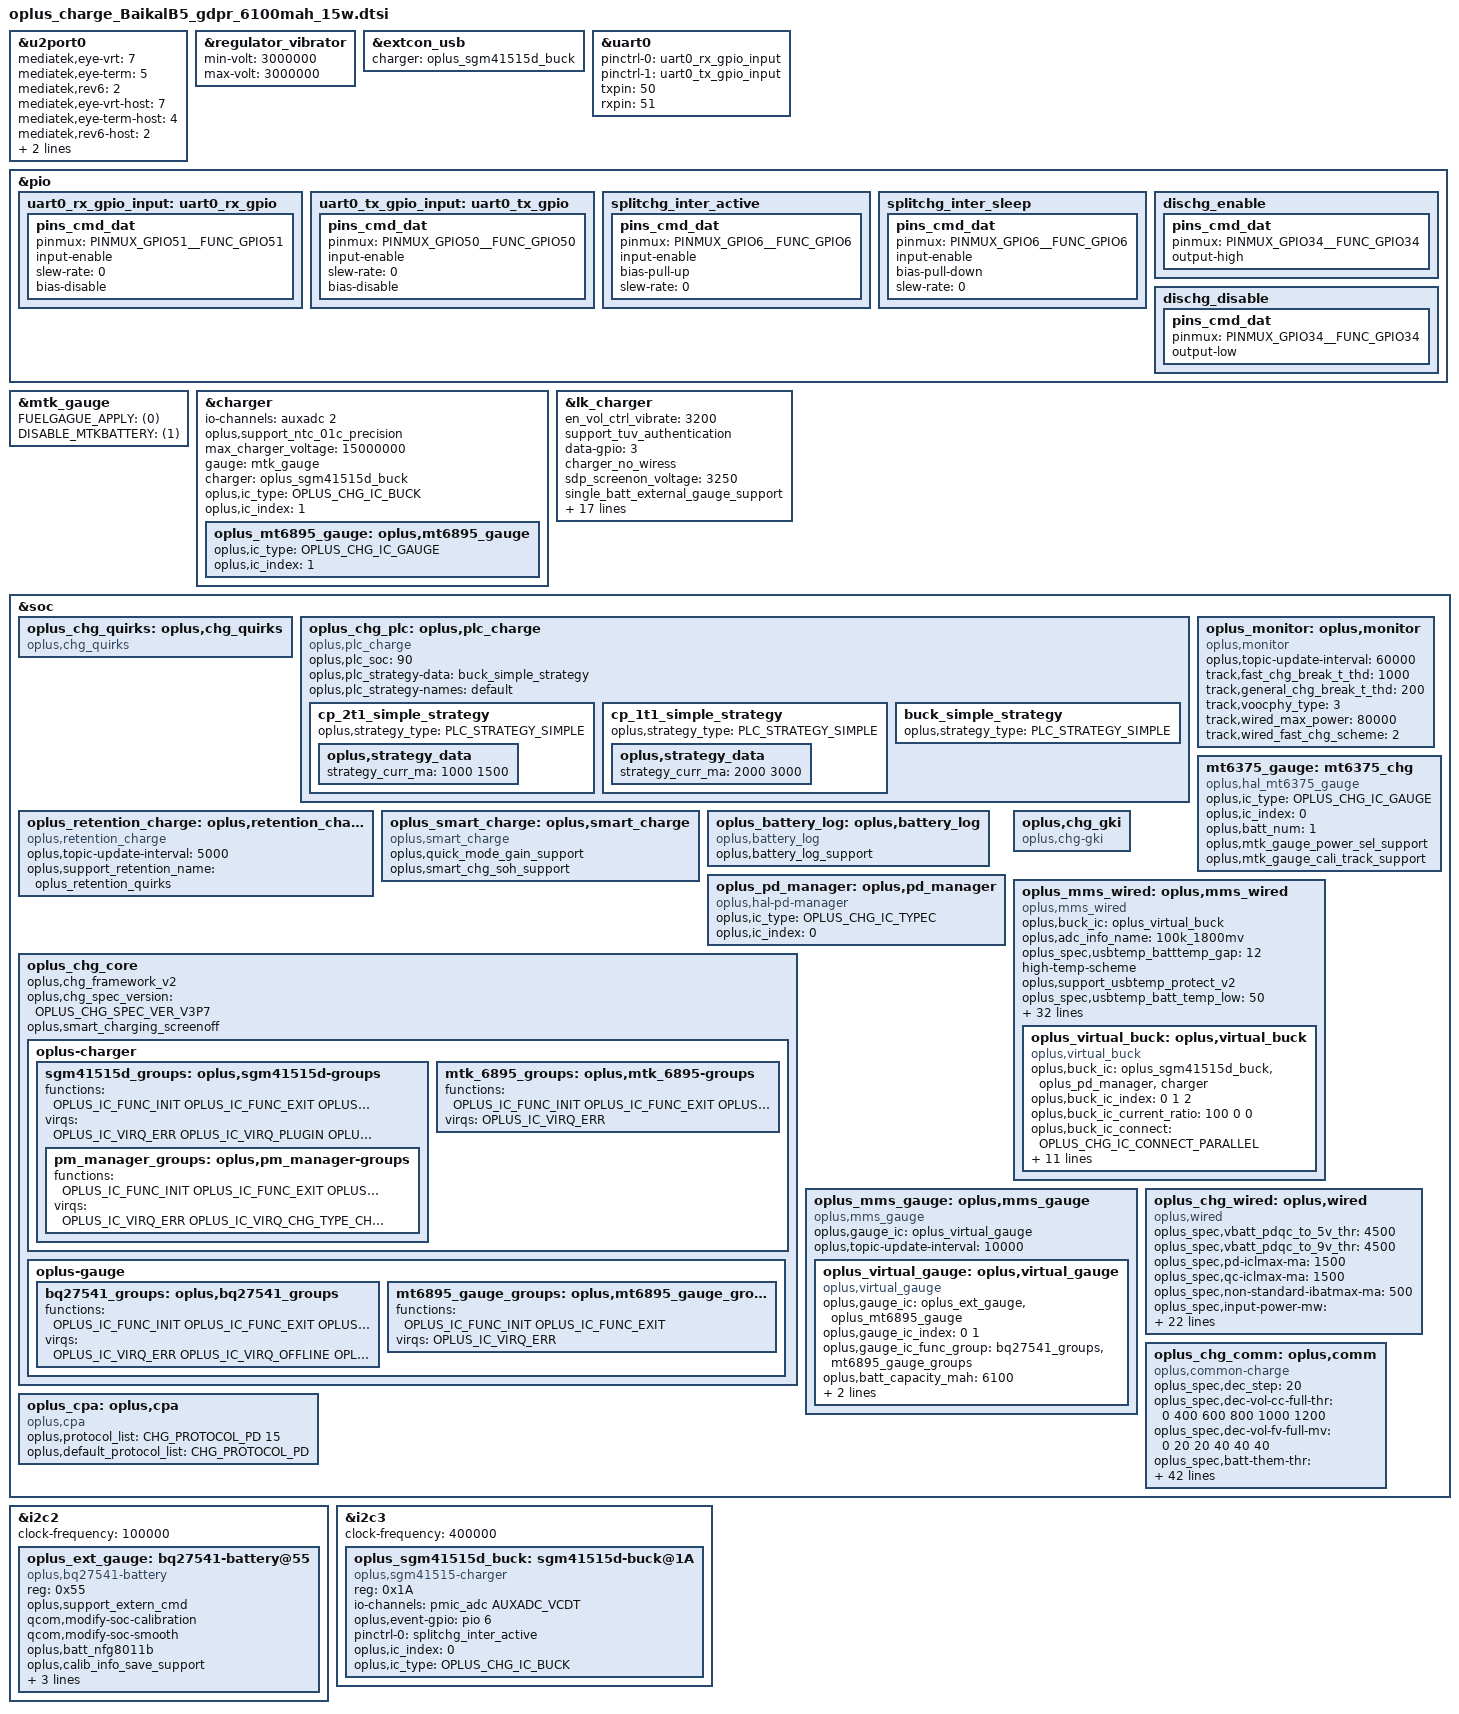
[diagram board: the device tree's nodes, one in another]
// SPDX-License-Identifier: GPL-2.0-only
/*
* Copyright (C) 2021-2020 Oplus. All rights reserved.
*/

/*
 * CPU:MT6835
 * Project:Baikal-B5
 * Module:CHG dtsi 15W support PD
 *
 * UART
 * UTXD0 -->GPIO50
 * URXD0 -->GPIO51
 *
 * I2C
 * MASTER_CHG(SGM41515D)        --> I2C3
 * CCLOGIC(AW35615)             --> I2C3
 * GAUGE                        --> I2C2
 *
 * IRQ
 * EINT5(PD IRQ)                -->GPIO5
 * EINT6(CHG IRQ)               -->GPIO6
 *
 * GPIO
 * MAIN/CCLOGIN_SCL             --> GPIO133(SCL3)
 * MAIN/CCLOGIN_SDA             --> GPIO134(SDA3)
 * GAUGE_SCL                    --> GPIO131(SCL2)
 * GAUGE_SDA                    --> GPIO132(SDA2)
 * VBUS_SHORT(防烧口)            --> GPIO34
 *
 * AP_AUXADC:
 * 0				--> FLASH_LED_NTC (flash light temperature)
 * 1				--> NA
 * 2				--> CHG_NTC(SGM41515D charger temperature)
 * 3				--> USB_TEM_ADC_PMU1(usb btb temperature)
 * 4				--> USB_TEM_ADC_PMU2(usb btb temperature)
 * 5				--> BAT_ID(battery id detect)
 * 6				-->
 * 7				-->
 * 8				-->
 */

#include <dt-bindings/iio/mt635x-auxadc.h>
#include <dt-bindings/pinctrl/mt6373-pinfunc.h>
#include <dt-bindings/pinctrl/mt65xx.h>
#include "oplus_chg.h"

&u2port0 {
	mediatek,eye-vrt = <7>;
	mediatek,eye-term= <5>;
	mediatek,rev6 = <2>;
	mediatek,eye-vrt-host = <7>;
	mediatek,eye-term-host = <4>;
	mediatek,rev6-host = <2>;
	mediatek,discth = <0xc>;
	mediatek,rx-sqth = <3>;
};

&regulator_vibrator{
	min-volt = <3000000>;
	max-volt = <3000000>;
};

&extcon_usb {
	charger = <&oplus_sgm41515d_buck>;
	status = "okay";
};

&uart0 {
	pinctrl-names = "uart0_rx_gpio", "uart0_tx_gpio";
	pinctrl-0 = <&uart0_rx_gpio_input>;
	pinctrl-1 = <&uart0_tx_gpio_input>;
	status = "okay";

	txpin = <50>;
	rxpin = <51>;
};

&pio {
	uart0_rx_gpio_input: uart0_rx_gpio {
		pins_cmd_dat {
			pinmux = <PINMUX_GPIO51__FUNC_GPIO51>;
			input-enable;
			slew-rate = <0>;
			bias-disable;
		};
	};

	uart0_tx_gpio_input: uart0_tx_gpio {
		pins_cmd_dat {
			pinmux = <PINMUX_GPIO50__FUNC_GPIO50>;
			input-enable;
			slew-rate = <0>;
			bias-disable;
		};
	};
	/*split_chg*/
	splitchg_inter_active: splitchg_inter_active {
		pins_cmd_dat {
			pinmux = <PINMUX_GPIO6__FUNC_GPIO6>;
			input-enable;
			bias-pull-up;
			slew-rate = <0>;
		};
	};
	splitchg_inter_sleep: splitchg_inter_sleep {
		pins_cmd_dat {
			pinmux = <PINMUX_GPIO6__FUNC_GPIO6>;
			input-enable;
			bias-pull-down;
			slew-rate = <0>;
		};
	};
	/*VBUS_SHORT*/
	dischg_enable: dischg_enable {
		pins_cmd_dat {
			pinmux = <PINMUX_GPIO34__FUNC_GPIO34>;
			output-high;
		};
	};
	dischg_disable: dischg_disable {
		pins_cmd_dat {
			pinmux = <PINMUX_GPIO34__FUNC_GPIO34>;
			output-low;
		};
	};
};


&mtk_gauge {
	FUELGAGUE_APPLY = <(0)>;
	DISABLE_MTKBATTERY = <(1)>;
};

&charger {
	io-channels = <&auxadc 2>;
	io-channel-names = "auxadc5-chargeric_temp";
	oplus,support_ntc_01c_precision;
	max_charger_voltage = <15000000>;
	gauge = <&mtk_gauge>;
	charger = <&oplus_sgm41515d_buck>;

	oplus,ic_type = <OPLUS_CHG_IC_BUCK>;
	oplus,ic_index = <1>;

	oplus_mt6895_gauge: oplus,mt6895_gauge {
		oplus,ic_type = <OPLUS_CHG_IC_GAUGE>;
		oplus,ic_index = <1>;
	};
};

&lk_charger {
	en_vol_ctrl_vibrate = <3200>;
	support_tuv_authentication;
	data-gpio = <3>;
	charger_no_wiress;
	sdp_screenon_voltage = <3250>;
	single_batt_external_gauge_support;
	support_sdp_screenoff;
	support_sdp_backlight;
	led_brightness = <102>;
	high-temp-scheme;
	over_high_temp_thr = <60>;
	charger_i2c_bus_id = <0x03>;
	support_quickboot_charge;
	support_4p48_single_battery;//待确定
	max_charger_voltage = <15000000>;
	boot_battery_voltage = <3400000>;
	usb_charger_current = <500000>;
	ac_charger_current = <2050000>;
	ac_charger_input_current = <1500000>;
	non_std_ac_charger_current = <750000>;
	charging_host_charger_current = <1500000>;
	ta_ac_charger_current = <1500000>;
	pd_charger_current = <500000>;
};

&soc {
	oplus_chg_quirks: oplus,chg_quirks {
		compatible = "oplus,chg_quirks";
	};

	oplus_chg_plc: oplus,plc_charge {
		compatible = "oplus,plc_charge";
		oplus,plc_soc = <90>;
		oplus,plc_strategy-data = <&buck_simple_strategy>;
		oplus,plc_strategy-names = "default";

		cp_2t1_simple_strategy: cp_2t1_simple_strategy {
			oplus,strategy_type = <PLC_STRATEGY_SIMPLE>;
			oplus,strategy_data {
				strategy_curr_ma = <1000 1500>;
			};
		};

		cp_1t1_simple_strategy: cp_1t1_simple_strategy {
			oplus,strategy_type = <PLC_STRATEGY_SIMPLE>;
			oplus,strategy_data {
				strategy_curr_ma = <2000 3000>;
			};
		};

		buck_simple_strategy: buck_simple_strategy {
			oplus,strategy_type = <PLC_STRATEGY_SIMPLE>;
		};
	};

	oplus_retention_charge: oplus,retention_charge {
		compatible = "oplus,retention_charge";
		oplus,topic-update-interval = <5000>;
		oplus,support_retention_name = "oplus_retention_quirks";
	};

	oplus_smart_charge: oplus,smart_charge {
		compatible = "oplus,smart_charge";
		oplus,quick_mode_gain_support;
		oplus,smart_chg_soh_support;
	};

	oplus_battery_log: oplus,battery_log {
		compatible = "oplus,battery_log";
		oplus,battery_log_support;
	};

	oplus_monitor: oplus,monitor {
		compatible = "oplus,monitor";
		oplus,topic-update-interval = <60000>;

		track,fast_chg_break_t_thd = <1000>;
		track,general_chg_break_t_thd = <200>;
		track,voocphy_type = <3>;
		track,wired_max_power = <80000>;
		track,wired_fast_chg_scheme = <2>;
	};

	mt6375_gauge: mt6375_chg {
		status = "okay";
		compatible = "oplus,hal_mt6375_gauge";

		oplus,ic_type = <OPLUS_CHG_IC_GAUGE>;
		oplus,ic_index = <0>;
		oplus,batt_num = <1>;
		oplus,mtk_gauge_power_sel_support;
		oplus,mtk_gauge_cali_track_support;
	};

	oplus_pd_manager: oplus,pd_manager{
		compatible = "oplus,hal-pd-manager";
		oplus,ic_type = <OPLUS_CHG_IC_TYPEC>;
		oplus,ic_index = <0>;
	};

	oplus,chg_gki {
		compatible = "oplus,chg-gki";
	};

	oplus_chg_core {
		oplus,chg_framework_v2;
		oplus,chg_spec_version = <OPLUS_CHG_SPEC_VER_V3P7>;
		oplus,smart_charging_screenoff;

		oplus-charger {
			sgm41515d_groups: oplus,sgm41515d-groups {
				functions = <
					OPLUS_IC_FUNC_INIT
					OPLUS_IC_FUNC_EXIT
					OPLUS_IC_FUNC_REG_DUMP
					OPLUS_IC_FUNC_SMT_TEST
					OPLUS_IC_FUNC_BUCK_INPUT_PRESENT
					OPLUS_IC_FUNC_BUCK_INPUT_SUSPEND
					OPLUS_IC_FUNC_BUCK_INPUT_IS_SUSPEND
					OPLUS_IC_FUNC_BUCK_OUTPUT_SUSPEND
					OPLUS_IC_FUNC_BUCK_OUTPUT_IS_SUSPEND
					OPLUS_IC_FUNC_BUCK_SET_ICL
					OPLUS_IC_FUNC_BUCK_GET_ICL
					OPLUS_IC_FUNC_BUCK_SET_FCC
					OPLUS_IC_FUNC_BUCK_SET_FV
					OPLUS_IC_FUNC_BUCK_SET_ITERM
					OPLUS_IC_FUNC_BUCK_SET_RECHG_VOL
					OPLUS_IC_FUNC_BUCK_GET_INPUT_CURR
					OPLUS_IC_FUNC_BUCK_GET_INPUT_VOL
					OPLUS_IC_FUNC_OTG_BOOST_ENABLE
					OPLUS_IC_FUNC_SET_OTG_BOOST_VOL
					OPLUS_IC_FUNC_SET_OTG_BOOST_CURR_LIMIT
					OPLUS_IC_FUNC_BUCK_AICL_ENABLE
					OPLUS_IC_FUNC_BUCK_AICL_RERUN
					OPLUS_IC_FUNC_BUCK_AICL_RESET
					OPLUS_IC_FUNC_BUCK_GET_CHARGER_TYPE
					OPLUS_IC_FUNC_BUCK_RERUN_BC12
					OPLUS_IC_FUNC_BUCK_QC_DETECT_ENABLE
					OPLUS_IC_FUNC_BUCK_SET_QC_CONFIG
					OPLUS_IC_FUNC_BUCK_SHIPMODE_ENABLE
					//OPLUS_IC_FUNC_BUCK_GET_USB_BTB_TEMP
					//OPLUS_IC_FUNC_BUCK_GET_BATT_BTB_TEMP
					OPLUS_IC_FUNC_BUCK_SET_AICL_POINT
					OPLUS_IC_FUNC_BUCK_HARDWARE_INIT
					OPLUS_IC_FUNC_BUCK_KICK_WDT
				>;
				virqs = <
					OPLUS_IC_VIRQ_ERR
					OPLUS_IC_VIRQ_PLUGIN
					OPLUS_IC_VIRQ_CHG_TYPE_CHANGE
					OPLUS_IC_VIRQ_BC12_COMPLETED
				>;
				pm_manager_groups: oplus,pm_manager-groups {
					functions = <
						OPLUS_IC_FUNC_INIT
						OPLUS_IC_FUNC_EXIT
						OPLUS_IC_FUNC_REG_DUMP
						OPLUS_IC_FUNC_SMT_TEST
						OPLUS_IC_FUNC_BUCK_GET_CHARGER_TYPE
						OPLUS_IC_FUNC_BUCK_GET_CC_ORIENTATION
						OPLUS_IC_FUNC_BUCK_SET_PD_CONFIG
						OPLUS_IC_FUNC_GET_TYPEC_MODE
						OPLUS_IC_FUNC_SET_TYPEC_MODE
						OPLUS_IC_FUNC_GET_TYPEC_ROLE
						OPLUS_IC_FUNC_GET_CHARGER_VOL_MAX
						OPLUS_IC_FUNC_GET_CHARGER_VOL_MIN
						OPLUS_IC_FUNC_GET_CHARGER_CURR_MAX
						OPLUS_IC_FUNC_BUCK_BC12_COMPLETED
						OPLUS_IC_FUNC_GET_OTG_ENABLE
						OPLUS_IC_FUNC_IS_OPLUS_SVID
						OPLUS_IC_FUNC_GET_DATA_ROLE
						OPLUS_IC_FUNC_FIXED_PDO_SET
						OPLUS_IC_FUNC_PPS_PDO_SET
						OPLUS_IC_FUNC_PPS_GET_PDO_INFO
					>;
					virqs = <
						OPLUS_IC_VIRQ_ERR
						OPLUS_IC_VIRQ_CHG_TYPE_CHANGE
						OPLUS_IC_VIRQ_SVID
						OPLUS_IC_VIRQ_VOLTAGE_CHANGED
						OPLUS_IC_VIRQ_CURRENT_CHANGED
						OPLUS_IC_VIRQ_OTG_ENABLE
						OPLUS_IC_VIRQ_DATA_ROLE_CHANGED
					>;
				};
			};
			mtk_6895_groups: oplus,mtk_6895-groups {
				functions = <
					OPLUS_IC_FUNC_INIT
					OPLUS_IC_FUNC_EXIT
					OPLUS_IC_FUNC_REG_DUMP
					OPLUS_IC_FUNC_SMT_TEST
				>;
				virqs = <
					OPLUS_IC_VIRQ_ERR
				>;
			};

		};

		oplus-gauge {
			bq27541_groups: oplus,bq27541_groups {
				functions = <
					OPLUS_IC_FUNC_INIT
					OPLUS_IC_FUNC_EXIT
					OPLUS_IC_FUNC_REG_DUMP
					OPLUS_IC_FUNC_SMT_TEST
					OPLUS_IC_FUNC_GAUGE_GET_BATT_VOL
					OPLUS_IC_FUNC_GAUGE_GET_BATT_MAX
					OPLUS_IC_FUNC_GAUGE_GET_BATT_MIN
					OPLUS_IC_FUNC_GAUGE_GET_BATT_CURR
					OPLUS_IC_FUNC_GAUGE_GET_BATT_TEMP
					OPLUS_IC_FUNC_GAUGE_GET_BATT_SOC
					OPLUS_IC_FUNC_GAUGE_GET_BATT_FCC
					OPLUS_IC_FUNC_GAUGE_GET_BATT_CC
					OPLUS_IC_FUNC_GAUGE_GET_BATT_RM
					OPLUS_IC_FUNC_GAUGE_GET_BATT_SOH
					OPLUS_IC_FUNC_GAUGE_GET_BATT_AUTH
					OPLUS_IC_FUNC_GAUGE_GET_BATT_HMAC
					OPLUS_IC_FUNC_GAUGE_SET_BATT_FULL
					OPLUS_IC_FUNC_GAUGE_UPDATE_DOD0
					OPLUS_IC_FUNC_GAUGE_UPDATE_SOC_SMOOTH
					OPLUS_IC_FUNC_GAUGE_GET_CB_STATUS
					OPLUS_IC_FUNC_GAUGE_GET_BATT_NUM
					OPLUS_IC_FUNC_GAUGE_GET_DEVICE_TYPE
					OPLUS_IC_FUNC_GAUGE_GET_DEVICE_TYPE_FOR_VOOC
					OPLUS_IC_FUNC_GAUGE_GET_BATT_FCC
					OPLUS_IC_FUNC_GAUGE_GET_BATT_FC
					OPLUS_IC_FUNC_GAUGE_GET_BATT_QM
					OPLUS_IC_FUNC_GAUGE_GET_BATT_PD
					OPLUS_IC_FUNC_GAUGE_GET_BATT_RCU
					OPLUS_IC_FUNC_GAUGE_GET_BATT_RCF
					OPLUS_IC_FUNC_GAUGE_GET_BATT_FCU
					OPLUS_IC_FUNC_GAUGE_GET_BATT_FCF
					OPLUS_IC_FUNC_GAUGE_GET_BATT_SOU
					OPLUS_IC_FUNC_GAUGE_GET_BATT_DO0
					OPLUS_IC_FUNC_GAUGE_GET_BATT_DOE
					OPLUS_IC_FUNC_GAUGE_GET_BATT_TRM
					OPLUS_IC_FUNC_GAUGE_GET_BATT_PC
					OPLUS_IC_FUNC_GAUGE_GET_BATT_QS
					OPLUS_IC_FUNC_GAUGE_IS_SUSPEND
					OPLUS_IC_FUNC_GAUGE_GET_BCC_PARMS
					OPLUS_IC_FUNC_GAUGE_FASTCHG_UPDATE_BCC_PARMS
					OPLUS_IC_FUNC_GAUGE_GET_PREV_BCC_PARMS
					OPLUS_IC_FUNC_GAUGE_SET_BCC_PARMS
					OPLUS_IC_FUNC_GAUGE_SET_PROTECT_CHECK
					OPLUS_IC_FUNC_GAUGE_GET_AFI_UPDATE_DONE
					OPLUS_IC_FUNC_GAUGE_CHECK_RESET
					OPLUS_IC_FUNC_GAUGE_SET_RESET
					OPLUS_IC_FUNC_GAUGE_GET_DEVICE_TYPE_FOR_BCC
					OPLUS_IC_FUNC_GAUGE_GET_DOD0
					OPLUS_IC_FUNC_GAUGE_GET_DOD0_PASSED_Q
					OPLUS_IC_FUNC_GAUGE_GET_QMAX
					OPLUS_IC_FUNC_GAUGE_GET_QMAX_PASSED_Q
					OPLUS_IC_FUNC_GAUGE_GET_REG_INFO
					OPLUS_IC_FUNC_GAUGE_GET_CALIB_TIME
					OPLUS_IC_FUNC_GAUGE_GET_GAUGE_TYPE
					OPLUS_IC_FUNC_GAUGE_GET_BATT_SN
					OPLUS_IC_FUNC_GAUGE_GET_MANU_DATE
					OPLUS_IC_FUNC_GAUGE_GET_FIRST_USAGE_DATE
					OPLUS_IC_FUNC_GAUGE_SET_FIRST_USAGE_DATE
					OPLUS_IC_FUNC_GAUGE_GET_UI_CC
					OPLUS_IC_FUNC_GAUGE_SET_UI_CC
					OPLUS_IC_FUNC_GAUGE_GET_UI_SOH
					OPLUS_IC_FUNC_GAUGE_SET_UI_SOH
					OPLUS_IC_FUNC_GAUGE_GET_USED_FLAG
					OPLUS_IC_FUNC_GAUGE_SET_USED_FLAG
					OPLUS_IC_FUNC_GAUGE_SET_SEAL_FLAG
				>;
				virqs = <
					OPLUS_IC_VIRQ_ERR
					OPLUS_IC_VIRQ_OFFLINE
					OPLUS_IC_VIRQ_RESUME
				>;
			};

			mt6895_gauge_groups: oplus,mt6895_gauge_groups {
				functions = <
					OPLUS_IC_FUNC_INIT
					OPLUS_IC_FUNC_EXIT
				>;
				virqs = <
					OPLUS_IC_VIRQ_ERR
				>;
			};
		};
	};
};

&soc {
	oplus_mms_wired: oplus,mms_wired {
		compatible = "oplus,mms_wired";
		oplus,buck_ic = <&oplus_virtual_buck>;
		oplus,adc_info_name = "100k_1800mv";
		oplus_spec,usbtemp_batttemp_gap = <12>;
		high-temp-scheme;

		oplus,support_usbtemp_protect_v2;
		oplus_spec,usbtemp_batt_temp_low = <50>;
		oplus_spec,usbtemp_batt_temp_high = <50>;
		oplus_spec,usbtemp_batt_temp_over_hot = <60>;
		oplus_spec,usbtemp_ntc_temp_low = <57>;
		oplus_spec,usbtemp_ntc_temp_high = <69>;
		oplus_spec,usbtemp_temp_gap_low_with_batt_temp = <7>;
		oplus_spec,usbtemp_temp_gap_with_batt_temp_in_over_hot = <15>;
		oplus_spec,usbtemp_temp_gap_high_with_batt_temp = <12>;
		oplus_spec,usbtemp_temp_gap_low_without_batt_temp = <12>;
		oplus_spec,usbtemp_temp_gap_high_without_batt_temp = <24>;
		oplus_spec,usbtemp_rise_fast_temp_low = <3>;
		oplus_spec,usbtemp_rise_fast_temp_high = <3>;
		oplus_spec,usbtemp_rise_fast_temp_count_low = <30>;
		oplus_spec,usbtemp_rise_fast_temp_count_high = <20>;
		oplus_spec,usbtemp_cool_down_ntc_low = <54>;
		oplus_spec,usbtemp_cool_down_ntc_high = <65>;
		oplus_spec,usbtemp_cool_down_gap_low = <12>;
		oplus_spec,usbtemp_cool_down_gap_high = <20>;
		oplus_spec,usbtemp_cool_down_recover_ntc_low = <48>;
		oplus_spec,usbtemp_cool_down_recover_ntc_high = <60>;
		oplus_spec,usbtemp_cool_down_recover_gap_low = <6>;
		oplus_spec,usbtemp_cool_down_recover_gap_high = <15>;
		oplus_virtual_buck: oplus,virtual_buck {
			compatible = "oplus,virtual_buck";
			oplus,buck_ic = <&oplus_sgm41515d_buck &oplus_pd_manager &charger>;
			oplus,buck_ic_index = <0 1 2>;
			oplus,buck_ic_current_ratio = <100 0 0>;
			oplus,buck_ic_connect = <OPLUS_CHG_IC_CONNECT_PARALLEL>;
			oplus,main_charger = <0>;
			oplus,buck_ic_func_group = <&sgm41515d_groups &pm_manager_groups &mtk_6895_groups>;
			oplus,ic_type = <OPLUS_CHG_IC_VIRTUAL_BUCK>;
			oplus,ic_index = <0>;
			oplus,dischg-gpio = <&pio 34 0x00>;/*VBUS_SHORT*/
			oplus,uart_tx-gpio = <&pio 50 0x00>;
			oplus,uart_rx-gpio = <&pio 51 0x00>;
			pinctrl-names = "dischg_enable", "dischg_disable";
			pinctrl-0 = <&dischg_enable>;
			pinctrl-1 = <&dischg_disable>;
			io-channels = <&auxadc 4>,<&auxadc 3>;
			io-channel-names = "usb_temp_adc_l","usb_temp_adc_r";
		};
	};
	oplus_mms_gauge: oplus,mms_gauge {
		compatible = "oplus,mms_gauge";
		oplus,gauge_ic = <&oplus_virtual_gauge>;
		oplus,topic-update-interval = <10000>;
		oplus_virtual_gauge: oplus,virtual_gauge {
			compatible = "oplus,virtual_gauge";
			oplus,gauge_ic = <&oplus_ext_gauge &oplus_mt6895_gauge>;
			oplus,gauge_ic_index = <0 1>;
			oplus,gauge_ic_func_group = <&bq27541_groups &mt6895_gauge_groups>;
			oplus,batt_capacity_mah = <6100>;
			oplus,ic_type = <OPLUS_CHG_IC_VIRTUAL_GAUGE>;
			oplus,ic_index = <0>;
		};
	};
};

&soc {
	oplus_chg_wired: oplus,wired {
		compatible = "oplus,wired";
		oplus_spec,vbatt_pdqc_to_5v_thr = <4500>;
		oplus_spec,vbatt_pdqc_to_9v_thr = <4500>;
		oplus_spec,pd-iclmax-ma = <1500>;
		oplus_spec,qc-iclmax-ma = <1500>;
		oplus_spec,non-standard-ibatmax-ma = <500>;
		oplus_spec,input-power-mw = <
			2500		/* OPLUS_WIRED_CHG_MODE_UNKNOWN */
			2500		/* OPLUS_WIRED_CHG_MODE_SDP */
			7500		/* OPLUS_WIRED_CHG_MODE_CDP */
			10000		/* OPLUS_WIRED_CHG_MODE_DCP */
			18000		/* OPLUS_WIRED_CHG_MODE_VOOC */
			13500		/* OPLUS_WIRED_CHG_MODE_QC */
			13500		/* OPLUS_WIRED_CHG_MODE_PD */
		>;
		oplus_spec,led_on-fccmax-ma = <0 1707 3300 3300 3300 3300 3300 1000 0>;
		oplus_spec,fccmax-ma-lv = <
			0 1200 2200 2200 2200 2200 2200 2200 0	/* OPLUS_WIRED_CHG_MODE_UNKNOWN */
			0 600  600  600  600  600  600  600  0	/* OPLUS_WIRED_CHG_MODE_SDP */
			0 1577 1600 1600 1600 1600 1600 1600 0	/* OPLUS_WIRED_CHG_MODE_CDP */
			0 1577 2200 2200 2200 2200 2200 2200 0	/* OPLUS_WIRED_CHG_MODE_DCP */
			0 1577 3300 3300 3300 3300 3300 3300 0	/* OPLUS_WIRED_CHG_MODE_VOOC */
			0 1577 3300 3300 3300 3300 3300 3300 0	/* OPLUS_WIRED_CHG_MODE_QC */
			0 1577 3300 3300 3300 3300 3300 3300 0	/* OPLUS_WIRED_CHG_MODE_PD */
		>;
		oplus_spec,fccmax-ma-hv = <
			0 1200 2200 2200 2200 2200 2200 2200 0	/* OPLUS_WIRED_CHG_MODE_UNKNOWN */
			0 600  600  600  600  600  600  600  0	/* OPLUS_WIRED_CHG_MODE_SDP */
			0 1577 1600 1600 1600 1600 1600 1600 0	/* OPLUS_WIRED_CHG_MODE_CDP */
			0 1577 2200 2200 2200 2200 2200 2200 0	/* OPLUS_WIRED_CHG_MODE_DCP */
			0 1577 3300 3300 3300 3300 3300 3300 0	/* OPLUS_WIRED_CHG_MODE_VOOC */
			0 1577 3300 3300 3300 3300 3300 3300 0	/* OPLUS_WIRED_CHG_MODE_QC */
			0 1577 3300 3300 3300 3300 3300 3300 0	/* OPLUS_WIRED_CHG_MODE_PD */
		>;

		oplus_spec,cool_down_sale_pdqc_vol_mv = <5000>;
		oplus_spec,cool_down_sale_pdqc_curr_ma = <1200>;
		oplus_spec,cool_down_pdqc_vol_mv = <5000 5000 5000 9000>;
		oplus_spec,cool_down_pdqc_curr_ma = <1200 1500 2000 1500>;
		oplus_spec,cool_down_vooc_curr_ma = <1200 1500 2000 2500 3000 3000>;
		oplus_spec,cool_down_normal_curr_ma = <1200 1500 2000>;

		oplus_spec,vbus_ov_thr_mv = <11000 11000>;
		oplus_spec,vbus_uv_thr_mv = <4300 4300>;

		/* first data is strategy used temp type */
		oplus,vooc_strategy_name = "cgcl";
		oplus,vooc_strategy_data = <OPLUS_STRATEGY_USE_BATT_TEMP
					    0   350 3000 1 0
					    330 370 3000 2 0
					    350 440 2200 2 1>;
	};

	oplus_chg_comm: oplus,comm {
		compatible = "oplus,common-charge";
		oplus_spec,dec_step = <20>;
		oplus_spec,dec-vol-cc-full-thr = <0 400 600 800 1000 1200>;
		oplus_spec,dec-vol-fv-full-mv = <0 20 20 40 40 40>;
		oplus_spec,batt-them-thr = <(-100) 0 50 120 160 350 450 530>;
		oplus_spec,iterm-ma = <326>;
		oplus_spec,removed_bat_decidegc = <390>; /*-39 degree*/
		oplus_spec,fv-mv = <4490 4490 4490 4490 4490 4490 4470 4130 4130>;
		oplus_spec,sw-fv-mv = <4440 4440 4440 4440 4440 4440 4420 4080 4080>;
		oplus_spec,hw-fv-inc-mv = <0 18 18 18 18 18 18 18 0>;
		oplus_spec,sw-over-fv-mv = <4500 4500 4500 4500 4500 4500 4480 4140 4140>;
		oplus_spec,sw-over-fv-dec-mv = <8>;
		oplus_spec,non-standard-sw-fv-mv = <3930>;
		oplus_spec,non-standard-fv-mv = <3980>;
		oplus_spec,non-standard-hw-fv-inc-mv = <18>;
		oplus_spec,non-standard-sw-over-fv-mv = <3990>;
		oplus_spec,non-standard-vbatdet-mv = <3680>;
		oplus_spec,wired-vbatdet-mv = <0 4190 4290 4390 4390 4390 4370 4030 0>;
		oplus_spec,fcc-gear-thr-mv = <4180>;
		oplus_spec,vbatt-ov-thr-mv = <4600>;

		oplus_spec,full_pre_ffc_judge;
		oplus_spec,full-pre-ffc-mv = <4485>;
		oplus_spec,ffc-temp-thr = <120 210 350 440>;
		oplus_spec,wired-ffc-step-max = <2>;
		oplus_spec,wired-ffc-fv-mv = <4630 4630>;

		oplus_spec,wired-ffc-fv-cutoff-mv = <4565 4525 4525
						     4565 4505 4505>;
		oplus_spec,wired-ffc-fcc-ma = <1500 1500 1500
					       1440 1000 1000>;
		oplus_spec,wired-ffc-fcc-cutoff-ma = <1300 1300 1300
						      1340 900 900>;
		oplus_spec,vbat_uv_thr_mv = <3300>;
		oplus_spec,vbat_charging_uv_thr_mv = <3200>;

		/*If use subboard NTC as battery temp, config it as 20, otherwise 0 */
		oplus_spec,tbatt_power_off_cali_temp = <0>;
		oplus_spec,poweroff_high_batt_temp = <720>;
		oplus_spec,poweroff_emergency_batt_temp = <770>;
		oplus,vooc_show_ui_soc_decimal;
		oplus,ui_soc_decimal_speedmin = <20>;
		oplus,gauge_stuck_jump_support;
		oplus,gauge_stuck_threshold = <15>;
		oplus,gauge_stuck_time = <50>;
	};

	oplus_cpa: oplus,cpa {
		compatible = "oplus,cpa";
		oplus,protocol_list = <CHG_PROTOCOL_PD 15>;
		oplus,default_protocol_list = <CHG_PROTOCOL_PD>;
	};
};

&i2c2 {
	status = "okay";
	clock-frequency = <100000>; //100K

	oplus_ext_gauge:bq27541-battery@55 {
		status = "okay";
		compatible = "oplus,bq27541-battery";
		reg = <0x55>;
		oplus,support_extern_cmd;
		qcom,modify-soc-calibration;
		qcom,modify-soc-smooth;
		oplus,batt_nfg8011b;
		oplus,calib_info_save_support;
		oplus,batt_num = <1>;
		oplus,ic_type = <OPLUS_CHG_IC_GAUGE>;
		oplus,ic_index = <0>;
	};
};

&i2c3 {
	status = "okay";
	clock-frequency = <400000>;//400K
	oplus_sgm41515d_buck:sgm41515d-buck@1A {
		status = "okay";
		compatible = "oplus,sgm41515-charger";
		reg = <0x1A>;

		io-channels = <&pmic_adc AUXADC_VCDT>;
		io-channel-names = "pmic_vcdt_voltage";

		oplus,event-gpio = <&pio 6 0x00>;
		pinctrl-names = "event_default";
		pinctrl-0 = <&splitchg_inter_active>;

		oplus,ic_index = <0>;
		oplus,ic_type = <OPLUS_CHG_IC_BUCK>;
	};
};


#include "mediatek/oplus_charge_BaikalB5_PD_15w.dtsi"
